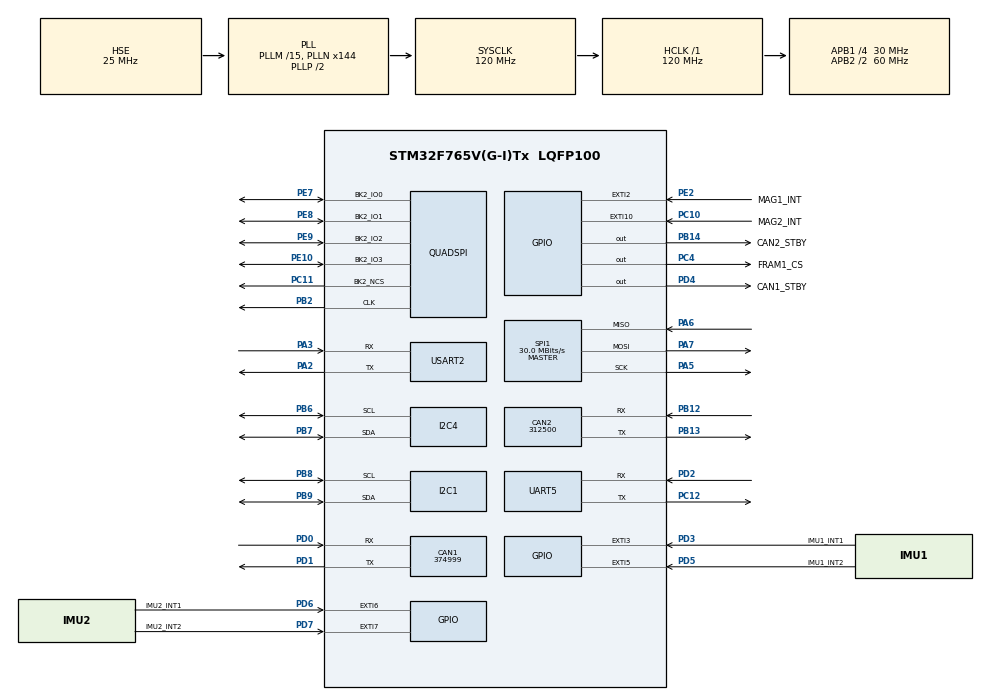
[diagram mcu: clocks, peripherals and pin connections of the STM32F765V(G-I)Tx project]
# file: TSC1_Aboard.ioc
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CAN1.BS1=CAN_BS1_2TQ
CAN1.BS2=CAN_BS2_2TQ
CAN1.CalculateBaudRate=374999
CAN1.CalculateTimeBit=2666
CAN1.CalculateTimeQuantum=533.3333333333334
CAN2.BS1=CAN_BS1_3TQ
CAN2.BS2=CAN_BS2_2TQ
CAN2.CalculateBaudRate=312500
CAN2.CalculateTimeBit=3200
CAN2.CalculateTimeQuantum=533.3333333333334
CORTEX_M7.CPU_DCache=Enabled
CORTEX_M7.CPU_ICache=Enabled
Dma.Request0=UART5_RX
Dma.Request1=UART5_TX
Dma.Request2=USART2_RX
Dma.Request3=USART2_TX
Dma.UART5_RX.0.Direction=DMA_PERIPH_TO_MEMORY
Dma.UART5_RX.0.FIFOMode=DMA_FIFOMODE_DISABLE
Dma.UART5_RX.0.Instance=DMA1_Stream0
Dma.UART5_RX.0.MemDataAlignment=DMA_MDATAALIGN_BYTE
Dma.UART5_RX.0.MemInc=DMA_MINC_ENABLE
Dma.UART5_RX.0.Mode=DMA_NORMAL
Dma.UART5_RX.0.PeriphDataAlignment=DMA_PDATAALIGN_BYTE
Dma.UART5_RX.0.PeriphInc=DMA_PINC_DISABLE
Dma.UART5_RX.0.Priority=DMA_PRIORITY_LOW
Dma.UART5_TX.1.Direction=DMA_MEMORY_TO_PERIPH
Dma.UART5_TX.1.FIFOMode=DMA_FIFOMODE_DISABLE
Dma.UART5_TX.1.Instance=DMA1_Stream7
Dma.UART5_TX.1.MemDataAlignment=DMA_MDATAALIGN_BYTE
Dma.UART5_TX.1.MemInc=DMA_MINC_ENABLE
Dma.UART5_TX.1.Mode=DMA_NORMAL
Dma.UART5_TX.1.PeriphDataAlignment=DMA_PDATAALIGN_BYTE
Dma.UART5_TX.1.PeriphInc=DMA_PINC_DISABLE
Dma.UART5_TX.1.Priority=DMA_PRIORITY_LOW
Dma.USART2_RX.2.Direction=DMA_PERIPH_TO_MEMORY
Dma.USART2_RX.2.FIFOMode=DMA_FIFOMODE_DISABLE
Dma.USART2_RX.2.Instance=DMA1_Stream5
Dma.USART2_RX.2.MemDataAlignment=DMA_MDATAALIGN_BYTE
Dma.USART2_RX.2.MemInc=DMA_MINC_ENABLE
Dma.USART2_RX.2.Mode=DMA_NORMAL
Dma.USART2_RX.2.PeriphDataAlignment=DMA_PDATAALIGN_BYTE
Dma.USART2_RX.2.PeriphInc=DMA_PINC_DISABLE
Dma.USART2_RX.2.Priority=DMA_PRIORITY_LOW
Dma.USART2_TX.3.Direction=DMA_MEMORY_TO_PERIPH
Dma.USART2_TX.3.FIFOMode=DMA_FIFOMODE_DISABLE
Dma.USART2_TX.3.Instance=DMA1_Stream6
Dma.USART2_TX.3.MemDataAlignment=DMA_MDATAALIGN_BYTE
Dma.USART2_TX.3.MemInc=DMA_MINC_ENABLE
Dma.USART2_TX.3.Mode=DMA_NORMAL
Dma.USART2_TX.3.PeriphDataAlignment=DMA_PDATAALIGN_BYTE
Dma.USART2_TX.3.PeriphInc=DMA_PINC_DISABLE
Dma.USART2_TX.3.Priority=DMA_PRIORITY_LOW
FREERTOS.Tasks01=defaultTask,24,128,StartDefaultTask,Default,NULL,Dynamic,NULL,NULL
FREERTOS.configENABLE_FPU=1
I2C1.Timing=0x007074AF
I2C4.Timing=0x007074AF
Mcu.Family=STM32F7
Mcu.Name=STM32F765V(G-I)Tx
Mcu.Package=LQFP100
NVIC.DMA1_Stream0_IRQn=true\:5\:0\:false\:false\:true\:true\:false\:true\:true
NVIC.DMA1_Stream5_IRQn=true\:5\:0\:false\:false\:true\:true\:false\:true\:true
NVIC.DMA1_Stream6_IRQn=true\:5\:0\:false\:false\:true\:true\:false\:true\:true
NVIC.DMA1_Stream7_IRQn=true\:5\:0\:false\:false\:true\:true\:false\:true\:true
NVIC.PriorityGroup=NVIC_PRIORITYGROUP_4
NVIC.RTC_WKUP_IRQn=true\:5\:0\:false\:false\:true\:true\:true\:true\:true
NVIC.TIM6_DAC_IRQn=true\:15\:0\:false\:false\:true\:false\:false\:true\:true
NVIC.TimeBase=TIM6_DAC_IRQn
NVIC.TimeBaseIP=TIM6
NVIC.UART5_IRQn=true\:5\:0\:false\:false\:true\:true\:true\:true\:true
NVIC.USART2_IRQn=true\:5\:0\:false\:false\:true\:true\:true\:true\:true
PA13.Mode=JTAG_4_pins
PA13.Signal=SYS_JTMS-SWDIO
PA14.Mode=JTAG_4_pins
PA14.Signal=SYS_JTCK-SWCLK
PA15.Mode=JTAG_4_pins
PA15.Signal=SYS_JTDI
PA2.Mode=Asynchronous
PA2.Signal=USART2_TX
PA3.Mode=Asynchronous
PA3.Signal=USART2_RX
PA5.Mode=Full_Duplex_Master
PA5.Signal=SPI1_SCK
PA6.Mode=Full_Duplex_Master
PA6.Signal=SPI1_MISO
PA7.Mode=Full_Duplex_Master
PA7.Signal=SPI1_MOSI
PB12.Mode=CAN_Activate
PB12.Signal=CAN2_RX
PB13.Mode=CAN_Activate
PB13.Signal=CAN2_TX
PB14.GPIO_Label=CAN2_STBY
PB14.Signal=GPIO_Output
PB2.Mode=Single Bank 2
PB2.Signal=QUADSPI_CLK
PB3.Mode=JTAG_4_pins
PB3.Signal=SYS_JTDO-SWO
PB6.Mode=I2C
PB6.Signal=I2C4_SCL
PB7.Mode=I2C
PB7.Signal=I2C4_SDA
PB8.Mode=I2C
PB8.Signal=I2C1_SCL
PB9.Mode=I2C
PB9.Signal=I2C1_SDA
PC10.GPIO_Label=MAG2_INT
PC10.Signal=GPXTI10
PC11.Mode=Single Bank 2
PC11.Signal=QUADSPI_BK2_NCS
PC12.Mode=Asynchronous
PC12.Signal=UART5_TX
PC14/OSC32_IN.Mode=LSE-External-Oscillator
PC14/OSC32_IN.Signal=RCC_OSC32_IN
PC15/OSC32_OUT.Mode=LSE-External-Oscillator
PC15/OSC32_OUT.Signal=RCC_OSC32_OUT
PC4.GPIO_Label=FRAM1_CS
PC4.Signal=GPIO_Output
PD0.Mode=CAN_Activate
PD0.Signal=CAN1_RX
PD1.Mode=CAN_Activate
PD1.Signal=CAN1_TX
PD2.Mode=Asynchronous
PD2.Signal=UART5_RX
PD3.GPIO_Label=IMU1_INT1
PD3.Signal=GPXTI3
PD4.GPIO_Label=CAN1_STBY
PD4.Signal=GPIO_Output
PD5.GPIO_Label=IMU1_INT2
PD5.Signal=GPXTI5
PD6.GPIO_Label=IMU2_INT1
PD6.Signal=GPXTI6
PD7.GPIO_Label=IMU2_INT2
PD7.Signal=GPXTI7
PE10.Mode=Single Bank 2
PE10.Signal=QUADSPI_BK2_IO3
PE2.GPIO_Label=MAG1_INT
PE2.Signal=GPXTI2
PE7.Mode=Single Bank 2
PE7.Signal=QUADSPI_BK2_IO0
PE8.Mode=Single Bank 2
PE8.Signal=QUADSPI_BK2_IO1
PE9.Mode=Single Bank 2
PE9.Signal=QUADSPI_BK2_IO2
PH0/OSC_IN.Mode=HSE-External-Oscillator
PH0/OSC_IN.Signal=RCC_OSC_IN
PH1/OSC_OUT.Mode=HSE-External-Oscillator
PH1/OSC_OUT.Signal=RCC_OSC_OUT
ProjectManager.HeapSize=0x200
ProjectManager.StackSize=0x400
ProjectManager.TargetToolchain=CMake
RCC.AHBFreq_Value=120000000
RCC.APB1CLKDivider=RCC_HCLK_DIV4
RCC.APB1Freq_Value=30000000
RCC.APB1TimFreq_Value=60000000
RCC.APB2CLKDivider=RCC_HCLK_DIV2
RCC.APB2Freq_Value=60000000
RCC.APB2TimFreq_Value=120000000
RCC.CortexFreq_Value=120000000
RCC.HCLKFreq_Value=120000000
RCC.HSE_VALUE=25000000
RCC.HSI_VALUE=16000000
RCC.PLLM=15
RCC.PLLN=144
RCC.PLLSourceVirtual=RCC_PLLSOURCE_HSE
RCC.SYSCLKFreq_VALUE=120000000
RCC.SYSCLKSource=RCC_SYSCLKSOURCE_PLLCLK
RCC.USBFreq_Value=120000000
RCC.VCOOutputFreq_Value=240000000
SPI1.CalculateBaudRate=30.0 MBits/s
SPI1.DataSize=SPI_DATASIZE_8BIT
SPI1.Direction=SPI_DIRECTION_2LINES
SPI1.Mode=SPI_MODE_MASTER
SPI1.VirtualType=VM_MASTER
USART2.VirtualMode-Asynchronous=VM_ASYNC
VP_FREERTOS_VS_CMSIS_V2.Mode=CMSIS_V2
VP_RTC_VS_RTC_Activate.Mode=RTC_Enabled
VP_RTC_VS_RTC_WakeUp_intern.Mode=WakeUp
VP_SYS_VS_tim6.Mode=TIM6
board=custom

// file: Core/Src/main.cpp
/* USER CODE BEGIN Header */
/**
  ******************************************************************************
  * @file           : main.c
  * @brief          : Main program body
  ******************************************************************************
  * @attention
  *
  * Copyright (c) 2025 STMicroelectronics.
  * All rights reserved.
  *
  * This software is licensed under terms that can be found in the LICENSE file
  * in the root directory of this software component.
  * If no LICENSE file comes with this software, it is provided AS-IS.
  *
  ******************************************************************************
  */
/* USER CODE END Header */
#include "main.h"
#include "cmsis_os.h"
#include "can.h"
#include "dma.h"
#include "i2c.h"
#include "quadspi.h"
#include "rtc.h"
#include "spi.h"
#include "usart.h"
#include "gpio.h"

void SystemClock_Config(void);
void MX_FREERTOS_Init(void);

int main(void)
{

  /* Enable the CPU Cache */

  /* Enable I-Cache---------------------------------------------------------*/
  SCB_EnableICache();

  /* Enable D-Cache---------------------------------------------------------*/
  SCB_EnableDCache();

  /* MCU Configuration--------------------------------------------------------*/

  /* Reset of all peripherals, Initializes the Flash interface and the Systick. */
  HAL_Init();

  /* Configure the system clock */
  SystemClock_Config();

  /* Initialize all configured peripherals */
  MX_GPIO_Init();
  MX_DMA_Init();
  MX_CAN1_Init();
  MX_CAN2_Init();
  MX_QUADSPI_Init();
  MX_SPI1_Init();
  MX_USART2_UART_Init();
  MX_RTC_Init();
  MX_UART5_Init();
  MX_I2C1_Init();
  MX_I2C4_Init();
  /* USER CODE BEGIN 2 */
  const char def[] = "test!\r\n";
  HAL_UART_Transmit(&huart2,(uint8_t*)"test2!\r\n",8,10);
  HAL_UART_Transmit(&huart5,(uint8_t*)"test5!\r\n",8,10);
  /* USER CODE END 2 */

  /* Init scheduler */
  osKernelInitialize();

  /* Call init function for freertos objects (in cmsis_os2.c) */
  MX_FREERTOS_Init();

  /* Start scheduler */
  osKernelStart();

  /* We should never get here as control is now taken by the scheduler */

  /* Infinite loop */
  while (1)
  {

  }
}

void SystemClock_Config(void)
{
  RCC_OscInitTypeDef RCC_OscInitStruct = {0};
  RCC_ClkInitTypeDef RCC_ClkInitStruct = {0};

  /** Configure LSE Drive Capability
  */
  HAL_PWR_EnableBkUpAccess();

  /** Configure the main internal regulator output voltage
  */
  __HAL_RCC_PWR_CLK_ENABLE();
  __HAL_PWR_VOLTAGESCALING_CONFIG(PWR_REGULATOR_VOLTAGE_SCALE3);

  /** Initializes the RCC Oscillators according to the specified parameters
  * in the RCC_OscInitTypeDef structure.
  */
  RCC_OscInitStruct.OscillatorType = RCC_OSCILLATORTYPE_LSI|RCC_OSCILLATORTYPE_HSE;
  RCC_OscInitStruct.HSEState = RCC_HSE_ON;
  RCC_OscInitStruct.LSIState = RCC_LSI_ON;
  RCC_OscInitStruct.PLL.PLLState = RCC_PLL_ON;
  RCC_OscInitStruct.PLL.PLLSource = RCC_PLLSOURCE_HSE;
  RCC_OscInitStruct.PLL.PLLM = 15;
  RCC_OscInitStruct.PLL.PLLN = 144;
  RCC_OscInitStruct.PLL.PLLP = RCC_PLLP_DIV2;
  RCC_OscInitStruct.PLL.PLLQ = 2;
  RCC_OscInitStruct.PLL.PLLR = 2;
  if (HAL_RCC_OscConfig(&RCC_OscInitStruct) != HAL_OK)
  {
    Error_Handler();
  }

  /** Initializes the CPU, AHB and APB buses clocks
  */
  RCC_ClkInitStruct.ClockType = RCC_CLOCKTYPE_HCLK|RCC_CLOCKTYPE_SYSCLK
                              |RCC_CLOCKTYPE_PCLK1|RCC_CLOCKTYPE_PCLK2;
  RCC_ClkInitStruct.SYSCLKSource = RCC_SYSCLKSOURCE_PLLCLK;
  RCC_ClkInitStruct.AHBCLKDivider = RCC_SYSCLK_DIV1;
  RCC_ClkInitStruct.APB1CLKDivider = RCC_HCLK_DIV4;
  RCC_ClkInitStruct.APB2CLKDivider = RCC_HCLK_DIV2;

  if (HAL_RCC_ClockConfig(&RCC_ClkInitStruct, FLASH_LATENCY_3) != HAL_OK)
  {
    Error_Handler();
  }
}

void HAL_TIM_PeriodElapsedCallback(TIM_HandleTypeDef *htim)
{
  if (htim->Instance == TIM6) {
    HAL_IncTick();
  }
}

void Error_Handler(void)
{
  __disable_irq();
  while (1)
  {
  }
}
